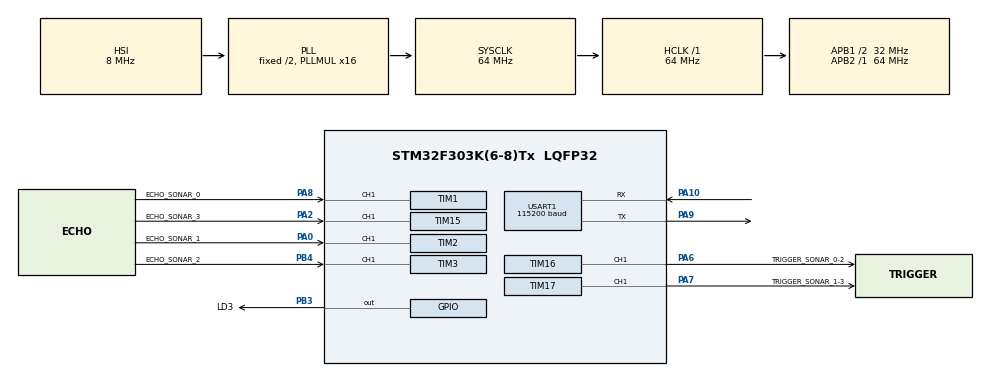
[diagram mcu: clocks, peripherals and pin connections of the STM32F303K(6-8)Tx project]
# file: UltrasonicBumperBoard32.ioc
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Mcu.Family=STM32F3
Mcu.Name=STM32F303K(6-8)Tx
Mcu.Package=LQFP32
NVIC.PriorityGroup=NVIC_PRIORITYGROUP_4
NVIC.TIM1_BRK_TIM15_IRQn=true\:0\:0\:false
NVIC.TIM1_CC_IRQn=true\:0\:0\:false
NVIC.TIM2_IRQn=true\:0\:0\:false
NVIC.TIM3_IRQn=true\:0\:0\:false
NVIC.TIM6_DAC1_IRQn=true\:0\:0\:false
NVIC.USART1_IRQn=true\:0\:0\:false
PA0.GPIO_Label=ECHO_SONAR_1
PA0.Signal=S_TIM2_CH1_ETR
PA10.Mode=Asynchronous
PA10.Signal=USART1_RX
PA13.GPIO_Label=SWDIO
PA13.Mode=Serial-Wire
PA13.Signal=SYS_JTMS-SWDIO
PA14.GPIO_Label=SWCLK
PA14.Mode=Serial-Wire
PA14.Signal=SYS_JTCK-SWCLK
PA2.GPIO_Label=ECHO_SONAR_3
PA2.Signal=S_TIM15_CH1
PA6.GPIO_Label=TRIGGER_SONAR_0-2
PA6.Signal=S_TIM16_CH1
PA7.GPIO_Label=TRIGGER_SONAR_1-3
PA7.Signal=S_TIM17_CH1
PA8.GPIO_Label=ECHO_SONAR_0
PA8.Signal=S_TIM1_CH1
PA9.Mode=Asynchronous
PA9.Signal=USART1_TX
PB3.GPIO_Label=LD3
PB3.Signal=GPIO_Output
PB4.GPIO_Label=ECHO_SONAR_2
PB4.Signal=S_TIM3_CH1
PF0\ /\ OSC_IN.GPIO_Label=MCO
PF0\ /\ OSC_IN.Signal=RCC_OSC_IN
ProjectManager.TargetToolchain=SW4STM32
RCC.AHBFreq_Value=64000000
RCC.APB1CLKDivider=RCC_HCLK_DIV2
RCC.APB1Freq_Value=32000000
RCC.APB1TimFreq_Value=64000000
RCC.APB2Freq_Value=64000000
RCC.APB2TimFreq_Value=64000000
RCC.CortexFreq_Value=64000000
RCC.HCLKFreq_Value=64000000
RCC.HSE_VALUE=8000000
RCC.HSI_VALUE=8000000
RCC.PLLMUL=RCC_PLL_MUL16
RCC.SYSCLKFreq_VALUE=64000000
RCC.SYSCLKSourceVirtual=RCC_SYSCLKSOURCE_PLLCLK
SH.S_TIM15_CH1.0=TIM15_CH1,Input_Capture1_from_TI1
SH.S_TIM15_CH1.1=TIM15_CH1,Input_Capture2_from_TI1
SH.S_TIM15_CH1.2=TIM15_CH1,TriggerSource_TI1FP1
SH.S_TIM16_CH1.0=TIM16_CH1,PWM Generation1 CH1
SH.S_TIM17_CH1.0=TIM17_CH1,PWM Generation1 CH1
SH.S_TIM1_CH1.0=TIM1_CH1,TriggerSource_TI1FP1
SH.S_TIM1_CH1.1=TIM1_CH1,Input_Capture1_from_TI1
SH.S_TIM1_CH1.2=TIM1_CH1,Input_Capture2_from_TI1
SH.S_TIM2_CH1_ETR.0=TIM2_CH1,TriggerSource_TI1FP1
SH.S_TIM2_CH1_ETR.1=TIM2_CH1,Input_Capture1_from_TI1
SH.S_TIM2_CH1_ETR.2=TIM2_CH1,Input_Capture2_from_TI1
SH.S_TIM3_CH1.0=TIM3_CH1,Input_Capture1_from_TI1
SH.S_TIM3_CH1.1=TIM3_CH1,Input_Capture2_from_TI1
SH.S_TIM3_CH1.2=TIM3_CH1,TriggerSource_TI1FP1
TIM1.Channel-Input_Capture2_from_TI1=TIM_CHANNEL_2
TIM1.ICPolarity_CH2=TIM_INPUTCHANNELPOLARITY_FALLING
TIM1.Period=65535
TIM1.Prescaler=630
TIM15.Channel-Input_Capture2_from_TI1=TIM_CHANNEL_2
TIM15.ICPolarity_CH2=TIM_INPUTCHANNELPOLARITY_FALLING
TIM15.Period=65535
TIM15.Prescaler=630
TIM16.OCFastMode_PWM=TIM_OCFAST_ENABLE
TIM16.OCMode_PWM=TIM_OCMODE_PWM2
TIM16.Period=65535
TIM16.Prescaler=63
TIM16.Pulse=65526
TIM17.OCFastMode_PWM=TIM_OCFAST_ENABLE
TIM17.OCMode_PWM=TIM_OCMODE_PWM2
TIM17.Period=65535
TIM17.Prescaler=63
TIM17.Pulse=65526
TIM2.Channel-Input_Capture2_from_TI1=TIM_CHANNEL_2
TIM2.ICPolarity_CH2=TIM_INPUTCHANNELPOLARITY_FALLING
TIM2.Period=65535
TIM2.Prescaler=630
TIM3.Channel-Input_Capture2_from_TI1=TIM_CHANNEL_2
TIM3.ICPolarity_CH2=TIM_INPUTCHANNELPOLARITY_FALLING
TIM3.Period=65535
TIM3.Prescaler=630
TIM6.Period=1000
TIM6.Prescaler=6400
USART1.BaudRate=115200
USART1.WordLength=UART_WORDLENGTH_8B
VP_TIM15_VS_ClockSourceINT.Mode=Internal
VP_TIM15_VS_ControllerModeReset.Mode=Reset Mode
VP_TIM16_VS_ClockSourceINT.Mode=Enable_Timer
VP_TIM16_VS_OPM.Mode=OPM_bit
VP_TIM17_VS_ClockSourceINT.Mode=Enable_Timer
VP_TIM17_VS_OPM.Mode=OPM_bit
VP_TIM1_VS_ClockSourceINT.Mode=Internal
VP_TIM1_VS_ControllerModeReset.Mode=Reset Mode
VP_TIM2_VS_ClockSourceINT.Mode=Internal
VP_TIM2_VS_ControllerModeReset.Mode=Reset Mode
VP_TIM3_VS_ClockSourceINT.Mode=Internal
VP_TIM3_VS_ControllerModeReset.Mode=Reset Mode
VP_TIM6_VS_ClockSourceINT.Mode=Enable_Timer
board=NUCLEO-F303K8

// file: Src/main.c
/**
  ******************************************************************************
  * File Name          : main.c
  * Description        : Main program body
  ******************************************************************************
  *
  * COPYRIGHT(c) 2016 STMicroelectronics
  *
  * Redistribution and use in source and binary forms, with or without modification,
  * are permitted provided that the following conditions are met:
  *   1. Redistributions of source code must retain the above copyright notice,
  *      this list of conditions and the following disclaimer.
  *   2. Redistributions in binary form must reproduce the above copyright notice,
  *      this list of conditions and the following disclaimer in the documentation
  *      and/or other materials provided with the distribution.
  *   3. Neither the name of STMicroelectronics nor the names of its contributors
  *      may be used to endorse or promote products derived from this software
  *      without specific prior written permission.
  *
  * THIS SOFTWARE IS PROVIDED BY THE COPYRIGHT HOLDERS AND CONTRIBUTORS "AS IS"
  * AND ANY EXPRESS OR IMPLIED WARRANTIES, INCLUDING, BUT NOT LIMITED TO, THE
  * IMPLIED WARRANTIES OF MERCHANTABILITY AND FITNESS FOR A PARTICULAR PURPOSE ARE
  * DISCLAIMED. IN NO EVENT SHALL THE COPYRIGHT HOLDER OR CONTRIBUTORS BE LIABLE
  * FOR ANY DIRECT, INDIRECT, INCIDENTAL, SPECIAL, EXEMPLARY, OR CONSEQUENTIAL
  * DAMAGES (INCLUDING, BUT NOT LIMITED TO, PROCUREMENT OF SUBSTITUTE GOODS OR
  * SERVICES; LOSS OF USE, DATA, OR PROFITS; OR BUSINESS INTERRUPTION) HOWEVER
  * CAUSED AND ON ANY THEORY OF LIABILITY, WHETHER IN CONTRACT, STRICT LIABILITY,
  * OR TORT (INCLUDING NEGLIGENCE OR OTHERWISE) ARISING IN ANY WAY OUT OF THE USE
  * OF THIS SOFTWARE, EVEN IF ADVISED OF THE POSSIBILITY OF SUCH DAMAGE.
  *
  ******************************************************************************
  */
#include "stm32f3xx_hal.h"
#include "tim.h"
#include "usart.h"
#include "gpio.h"

/* USER CODE BEGIN Includes */
#include "ultrasnd_handler.h"
#include "ser_handler.h"
#include "gpio.h"
/* USER CODE END Includes */

/* USER CODE BEGIN PV */
/* Private variables ---------------------------------------------------------*/

/* USER CODE END PV */

void SystemClock_Config(void);

/* USER CODE BEGIN PFP */
/* Private function prototypes -----------------------------------------------*/

/* USER CODE END PFP */

int main(void)
{

  /* MCU Configuration----------------------------------------------------------*/

  /* Reset of all peripherals, Initializes the Flash interface and the Systick. */
  HAL_Init();

  /* Configure the system clock */
  SystemClock_Config();

  /* Initialize all configured peripherals */
  MX_GPIO_Init();
  MX_TIM1_Init();
  MX_TIM2_Init();
  MX_TIM3_Init();
  MX_TIM6_Init();
  MX_TIM15_Init();
  MX_TIM16_Init();
  MX_TIM17_Init();
  MX_USART1_UART_Init();

  /* USER CODE BEGIN 2 */
  HAL_TIM_Base_Start_IT( &htim6 ); // 100 msec timer
  initSonar( MAX_SONAR );
  initSerOutput();
  /* USER CODE END 2 */

  /* Infinite loop */
  while (1)
  {

  /* USER CODE BEGIN 3 */
    // >>>>> Sonar reading
    triggerSonar( COUPLE_0_2 );
    HAL_Delay( 49 );
    triggerSonar( COUPLE_1_3 );
    HAL_Delay( 49 );
    // <<<<< Sonar reading

    // >>>>> Serial Output
    convertMeasures();
    sendMeasures();
    // <<<<< Serial Output
  }
  /* USER CODE END 3 */

}

/** System Clock Configuration
*/
void SystemClock_Config(void)
{

  RCC_OscInitTypeDef RCC_OscInitStruct;
  RCC_ClkInitTypeDef RCC_ClkInitStruct;
  RCC_PeriphCLKInitTypeDef PeriphClkInit;

  RCC_OscInitStruct.OscillatorType = RCC_OSCILLATORTYPE_HSI;
  RCC_OscInitStruct.HSIState = RCC_HSI_ON;
  RCC_OscInitStruct.HSICalibrationValue = 16;
  RCC_OscInitStruct.PLL.PLLState = RCC_PLL_ON;
  RCC_OscInitStruct.PLL.PLLSource = RCC_PLLSOURCE_HSI;
  RCC_OscInitStruct.PLL.PLLMUL = RCC_PLL_MUL16;
  HAL_RCC_OscConfig(&RCC_OscInitStruct);

  RCC_ClkInitStruct.ClockType = RCC_CLOCKTYPE_SYSCLK|RCC_CLOCKTYPE_PCLK1;
  RCC_ClkInitStruct.SYSCLKSource = RCC_SYSCLKSOURCE_PLLCLK;
  RCC_ClkInitStruct.AHBCLKDivider = RCC_SYSCLK_DIV1;
  RCC_ClkInitStruct.APB1CLKDivider = RCC_HCLK_DIV2;
  RCC_ClkInitStruct.APB2CLKDivider = RCC_HCLK_DIV1;
  HAL_RCC_ClockConfig(&RCC_ClkInitStruct, FLASH_LATENCY_2);

  PeriphClkInit.PeriphClockSelection = RCC_PERIPHCLK_USART1|RCC_PERIPHCLK_TIM1;
  PeriphClkInit.Usart1ClockSelection = RCC_USART1CLKSOURCE_PCLK1;
  PeriphClkInit.Tim1ClockSelection = RCC_TIM1CLK_HCLK;
  HAL_RCCEx_PeriphCLKConfig(&PeriphClkInit);

  HAL_SYSTICK_Config(HAL_RCC_GetHCLKFreq()/1000);

  HAL_SYSTICK_CLKSourceConfig(SYSTICK_CLKSOURCE_HCLK);

  /* SysTick_IRQn interrupt configuration */
  HAL_NVIC_SetPriority(SysTick_IRQn, 0, 0);
}

/************************ (C) COPYRIGHT STMicroelectronics *****END OF FILE****/
